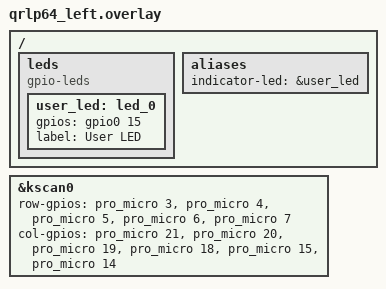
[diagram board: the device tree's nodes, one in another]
#include "qrlp64.dtsi" // Notice that the main dtsi files are included in the overlay.

#include <dt-bindings/zmk/mouse.h>

/ {

    leds {
        compatible = "gpio-leds";
        user_led: led_0 {
            gpios = <&gpio0 15 GPIO_ACTIVE_HIGH>;
            label = "User LED";
        };
    };

    aliases {
        indicator-led = &user_led;
    };
};

&kscan0 {
row-gpios
= <&pro_micro 3 (GPIO_ACTIVE_HIGH  | GPIO_PULL_DOWN)>
, <&pro_micro 4 (GPIO_ACTIVE_HIGH  | GPIO_PULL_DOWN)>
, <&pro_micro 5 (GPIO_ACTIVE_HIGH  | GPIO_PULL_DOWN)>
, <&pro_micro 6 (GPIO_ACTIVE_HIGH  | GPIO_PULL_DOWN)>
, <&pro_micro 7 (GPIO_ACTIVE_HIGH  | GPIO_PULL_DOWN)>
;
	col-gpios
		= <&pro_micro 21 GPIO_ACTIVE_HIGH>
		, <&pro_micro 20 GPIO_ACTIVE_HIGH>
		, <&pro_micro 19 GPIO_ACTIVE_HIGH>
		, <&pro_micro 18 GPIO_ACTIVE_HIGH>
		, <&pro_micro 15 GPIO_ACTIVE_HIGH>
		, <&pro_micro 14 GPIO_ACTIVE_HIGH>
		;
};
